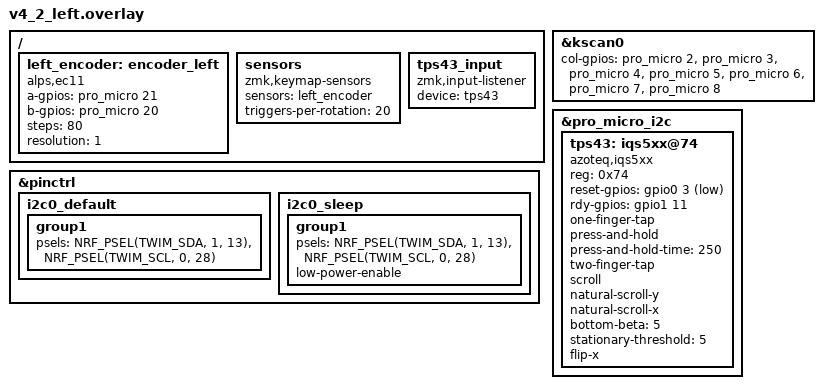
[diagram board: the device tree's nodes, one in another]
/*
 * Copyright (c) 2022 The ZMK Contributors
 *
 * SPDX-License-Identifier: MIT
 */

#include "v4_2.dtsi"

&kscan0 {
    col-gpios
        = <&pro_micro 2 GPIO_ACTIVE_HIGH>
        , <&pro_micro 3 GPIO_ACTIVE_HIGH>
        , <&pro_micro 4 GPIO_ACTIVE_HIGH>
        , <&pro_micro 5 GPIO_ACTIVE_HIGH>
        , <&pro_micro 6 GPIO_ACTIVE_HIGH>
        , <&pro_micro 7 GPIO_ACTIVE_HIGH>
        , <&pro_micro 8 GPIO_ACTIVE_HIGH>
        ;
};

#include <dt-bindings/pinctrl/nrf-pinctrl.h>

&pinctrl {
    i2c0_default: i2c0_default {
        group1 {
            psels = <NRF_PSEL(TWIM_SDA, 1, 13)>,
                    <NRF_PSEL(TWIM_SCL, 0, 28)>;
        };
    };

    i2c0_sleep: i2c0_sleep {
        group1 {
            psels = <NRF_PSEL(TWIM_SDA, 1, 13)>,
                    <NRF_PSEL(TWIM_SCL, 0, 28)>;
            low-power-enable;
        };
    };
};

&pro_micro_i2c {
    status = "okay";

    tps43: iqs5xx@74 {
        compatible = "azoteq,iqs5xx";
        status = "okay";
        reg = <0x74>;
        reset-gpios = <&gpio0 3 GPIO_ACTIVE_LOW>;
        rdy-gpios = <&gpio1 11 GPIO_ACTIVE_HIGH>;
        
        one-finger-tap;
        press-and-hold;
        press-and-hold-time = <250>;
        two-finger-tap;
        scroll;
        natural-scroll-y;
        natural-scroll-x;
        bottom-beta = <5>;
        stationary-threshold = <5>;
        flip-x;
    };
};

/ {
    left_encoder: encoder_left {
        compatible = "alps,ec11";
        a-gpios = <&pro_micro 21 (GPIO_ACTIVE_HIGH | GPIO_PULL_UP)>;
        b-gpios = <&pro_micro 20 (GPIO_ACTIVE_HIGH | GPIO_PULL_UP)>;
        steps = <80>;
        resolution = <1>;
        status = "okay";
    };

    sensors: sensors {
        compatible = "zmk,keymap-sensors";
        sensors = <&left_encoder>;
        triggers-per-rotation = <20>;
    };
};

/ {
    tps43_input: tps43_input {
        compatible = "zmk,input-listener";
        device = <&tps43>;
    };
};
